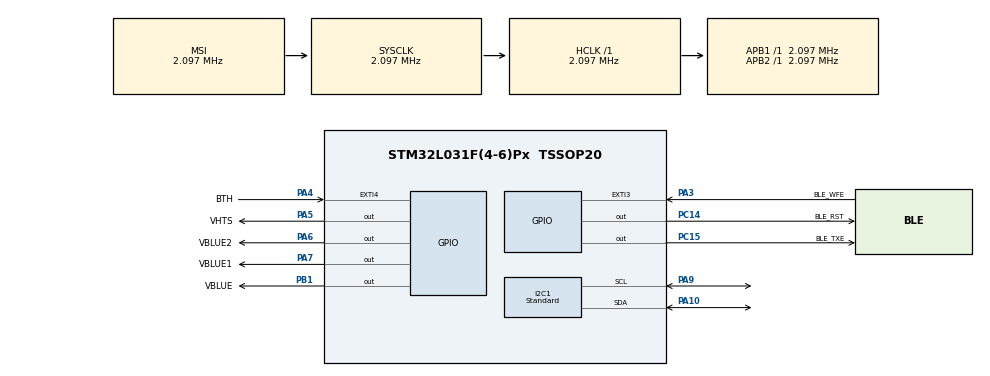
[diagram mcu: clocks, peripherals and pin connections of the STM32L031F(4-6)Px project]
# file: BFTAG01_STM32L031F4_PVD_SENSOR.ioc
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I2C1.DualAddressMode=I2C_DUALADDRESS_DISABLE
I2C1.GeneralCallMode=I2C_GENERALCALL_DISABLE
I2C1.I2C_Speed_Mode=I2C_Standard
I2C1.NoStretchMode=I2C_NOSTRETCH_DISABLE
I2C1.OwnAddress=10
I2C1.Speed=10
I2C1.Timing=0x000006C5
LPTIM1.ClockPrescaler=LPTIM_PRESCALER_DIV128
LPTIM1.UpdateMode=LPTIM_UPDATE_ENDOFPERIOD
Mcu.Family=STM32L0
Mcu.Name=STM32L031F(4-6)Px
Mcu.Package=TSSOP20
NVIC.EXTI2_3_IRQn=true\:2\:0\:true\:false\:true\:true\:true
NVIC.EXTI4_15_IRQn=true\:1\:0\:true\:false\:true\:true\:true
NVIC.PVD_IRQn=true\:0\:0\:false\:false\:true\:true\:true
PA10.Mode=I2C
PA10.Signal=I2C1_SDA
PA13.Mode=Serial_Wire
PA13.Signal=SYS_SWDIO
PA14.Mode=Serial_Wire
PA14.Signal=SYS_SWCLK
PA3.GPIO_Label=BLE_WFE
PA3.GPIO_ModeDefaultEXTI=GPIO_MODE_IT_FALLING
PA3.GPIO_PuPd=GPIO_NOPULL
PA3.Signal=GPXTI3
PA4.GPIO_Label=BTH
PA4.Signal=GPXTI4
PA5.GPIO_Label=VHTS
PA5.Signal=GPIO_Output
PA6.GPIO_Label=VBLUE2
PA6.Signal=GPIO_Output
PA7.GPIO_Label=VBLUE1
PA7.Signal=GPIO_Output
PA9.Mode=I2C
PA9.Signal=I2C1_SCL
PB1.GPIO_Label=VBLUE
PB1.Signal=GPIO_Output
PC14-OSC32_IN.GPIO_Label=BLE_RST
PC14-OSC32_IN.Signal=GPIO_Output
PC15-OSC32_OUT.GPIO_Label=BLE_TXE
PC15-OSC32_OUT.Signal=GPIO_Output
ProjectManager.HeapSize=0x200
ProjectManager.StackSize=0x400
ProjectManager.TargetToolchain=STM32CubeIDE
RCC.AHBFreq_Value=2097000
RCC.APB1Freq_Value=2097000
RCC.APB1TimFreq_Value=2097000
RCC.APB2Freq_Value=2097000
RCC.APB2TimFreq_Value=2097000
RCC.HSE_VALUE=8000000
RCC.HSI16_VALUE=16000000
RCC.HSI_VALUE=16000000
RCC.LSE_VALUE=32768
RCC.LptimClockSelection=RCC_LPTIM1CLKSOURCE_LSI
RCC.MSI_VALUE=2097000
RCC.PWR_Regulator_Voltage_Scale=PWR_REGULATOR_VOLTAGE_SCALE3
RCC.SYSCLKFreq_VALUE=2097000
RCC.VCOOutputFreq_Value=48000000
VP_LPTIM1_VS_LPTIM_counterModeInternalClock.Mode=Counts__internal_clock_event_00
board=custom

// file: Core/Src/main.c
/* USER CODE BEGIN Header */
/**
 ******************************************************************************
 * @file           : main.c
 * @brief          : Main program body
 ******************************************************************************
 * @attention
 *
 * <h2><center>&copy; Copyright (c) 2020 STMicroelectronics.
 * All rights reserved.</center></h2>
 *
 * This software component is licensed by ST under BSD 3-Clause license,
 * the "License"; You may not use this file except in compliance with the
 * License. You may obtain a copy of the License at:
 *                        opensource.org/licenses/BSD-3-Clause
 *
 ******************************************************************************
 */
/* USER CODE END Header */
#include "main.h"
#include "i2c.h"
#include "lptim.h"
#include "gpio.h"

/* USER CODE BEGIN Includes */
#include "config.h"
/* USER CODE END Includes */

void SystemClock_Config(void);

int main(void)
{

  /* MCU Configuration--------------------------------------------------------*/

  /* Reset of all peripherals, Initializes the Flash interface and the Systick. */
  HAL_Init();

  /* Configure the system clock */
  SystemClock_Config();

  /* Initialize all configured peripherals */
  MX_GPIO_Init();
  MX_LPTIM1_Init();
  MX_I2C1_Init();
  /* USER CODE BEGIN 2 */
	My_Main();
  /* USER CODE END 2 */

  /* Infinite loop */
	while (1)
	{

    /* USER CODE BEGIN 3 */
		My_While();
	}
  /* USER CODE END 3 */
}

void SystemClock_Config(void)
{
  RCC_OscInitTypeDef RCC_OscInitStruct = {0};
  RCC_ClkInitTypeDef RCC_ClkInitStruct = {0};
  RCC_PeriphCLKInitTypeDef PeriphClkInit = {0};

  /** Configure the main internal regulator output voltage
  */
  __HAL_PWR_VOLTAGESCALING_CONFIG(PWR_REGULATOR_VOLTAGE_SCALE3);
  /** Initializes the RCC Oscillators according to the specified parameters
  * in the RCC_OscInitTypeDef structure.
  */
  RCC_OscInitStruct.OscillatorType = RCC_OSCILLATORTYPE_LSI|RCC_OSCILLATORTYPE_MSI;
  RCC_OscInitStruct.LSIState = RCC_LSI_ON;
  RCC_OscInitStruct.MSIState = RCC_MSI_ON;
  RCC_OscInitStruct.MSICalibrationValue = 0;
  RCC_OscInitStruct.MSIClockRange = RCC_MSIRANGE_5;
  RCC_OscInitStruct.PLL.PLLState = RCC_PLL_NONE;
  if (HAL_RCC_OscConfig(&RCC_OscInitStruct) != HAL_OK)
  {
    Error_Handler();
  }
  /** Initializes the CPU, AHB and APB buses clocks
  */
  RCC_ClkInitStruct.ClockType = RCC_CLOCKTYPE_HCLK|RCC_CLOCKTYPE_SYSCLK
                              |RCC_CLOCKTYPE_PCLK1|RCC_CLOCKTYPE_PCLK2;
  RCC_ClkInitStruct.SYSCLKSource = RCC_SYSCLKSOURCE_MSI;
  RCC_ClkInitStruct.AHBCLKDivider = RCC_SYSCLK_DIV1;
  RCC_ClkInitStruct.APB1CLKDivider = RCC_HCLK_DIV1;
  RCC_ClkInitStruct.APB2CLKDivider = RCC_HCLK_DIV1;

  if (HAL_RCC_ClockConfig(&RCC_ClkInitStruct, FLASH_LATENCY_0) != HAL_OK)
  {
    Error_Handler();
  }
  PeriphClkInit.PeriphClockSelection = RCC_PERIPHCLK_I2C1|RCC_PERIPHCLK_LPTIM1;
  PeriphClkInit.I2c1ClockSelection = RCC_I2C1CLKSOURCE_PCLK1;
  PeriphClkInit.LptimClockSelection = RCC_LPTIM1CLKSOURCE_LSI;

  if (HAL_RCCEx_PeriphCLKConfig(&PeriphClkInit) != HAL_OK)
  {
    Error_Handler();
  }
}

void Error_Handler(void)
{
}

/************************ (C) COPYRIGHT STMicroelectronics *****END OF FILE****/
